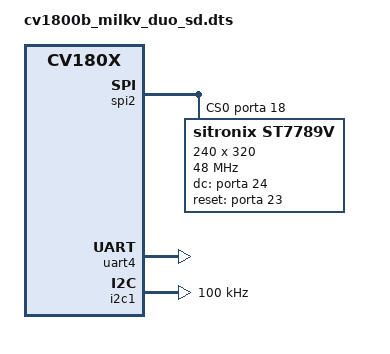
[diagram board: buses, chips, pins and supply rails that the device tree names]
/dts-v1/;
#include "cv180x_base_riscv.dtsi"
#include "cv180x_asic_qfn.dtsi"
#include "cv180x_asic_sd.dtsi"
#include "cv180x_default_memmap.dtsi"

&mipi_rx{
	snsr-reset = <&portc 8 GPIO_ACTIVE_LOW>, <&portc 8 GPIO_ACTIVE_LOW>, <&portc 8 GPIO_ACTIVE_LOW>;
};

&spi2 {
        status = "okay";
        cs-gpios = <&porta 18 0>;

        spidev@0 {
                status = "disabled";
};

        st7789v: st7789v@0{
                compatible = "sitronix,st7789v";
                reg = <0>;
                status = "okay";
                spi-max-frequency = <48000000>;
                spi-cpol;
                spi-cpha;
                
		//Waveshare 1.54" ST7789V
		//https://www.waveshare.com/product/1.54inch-lcd-module.htm
		//width = <240>;
		//height = <240>;
		//rotate = <0>; //This depends on your screen

		//Waveshare 2.0" ST7789VW
		//https://www.waveshare.com/2inch-lcd-module.htm
		width = <240>;
		height = <320>;
                rotate = <270>; //This depends on your screen

		fps = <60>;
                rgb;
                buswidth = <8>;
                dc-gpios = <&porta 24 GPIO_ACTIVE_HIGH>;
                reset-gpios = <&porta 23 GPIO_ACTIVE_HIGH>;
                debug = <0x4000000>;
        };
};

&uart4 {
	status = "okay";
};

&i2c1 {
       status = "okay";
       clock-frequency = <100000>;
};

/ {

};

